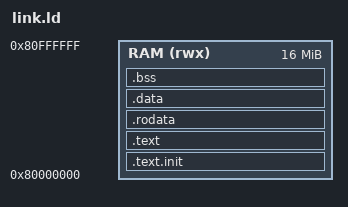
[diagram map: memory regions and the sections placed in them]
OUTPUT_ARCH(riscv)
ENTRY(_start)

MEMORY {
  RAM (rwx) : ORIGIN = 0x80000000, LENGTH = 16M
}

SECTIONS {
  .text.init : {
    *(.text.init)
  } > RAM

  .text : {
    *(.text .text.*)
  } > RAM

  .rodata : { *(.rodata*) } > RAM

  .data : { *(.data*) } > RAM

  .bss : {
    *(.bss*)
    *(COMMON)
  } > RAM

  /DISCARD/ : { *(.comment) *(.note*) }
}
